VERSION "ev-bms-module-1.0"

NS_ :

BS_:

BU_: BMS VCU

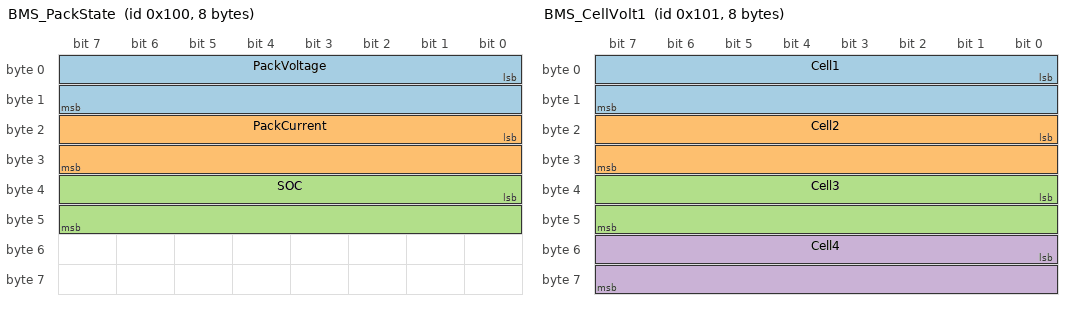
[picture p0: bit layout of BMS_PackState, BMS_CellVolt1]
BO_ 256 BMS_PackState: 8 BMS
 SG_ PackVoltage : 0|16@1+ (0.01,0) [0|655.35] "V" VCU
 SG_ PackCurrent : 16|16@1- (0.1,0) [-3276.8|3276.7] "A" VCU
 SG_ SOC : 32|16@1+ (0.01,0) [0|100] "%" VCU

BO_ 257 BMS_CellVolt1: 8 BMS
 SG_ Cell1 : 0|16@1+ (0.001,0) [0|65.535] "V" VCU
 SG_ Cell2 : 16|16@1+ (0.001,0) [0|65.535] "V" VCU
 SG_ Cell3 : 32|16@1+ (0.001,0) [0|65.535] "V" VCU
 SG_ Cell4 : 48|16@1+ (0.001,0) [0|65.535] "V" VCU

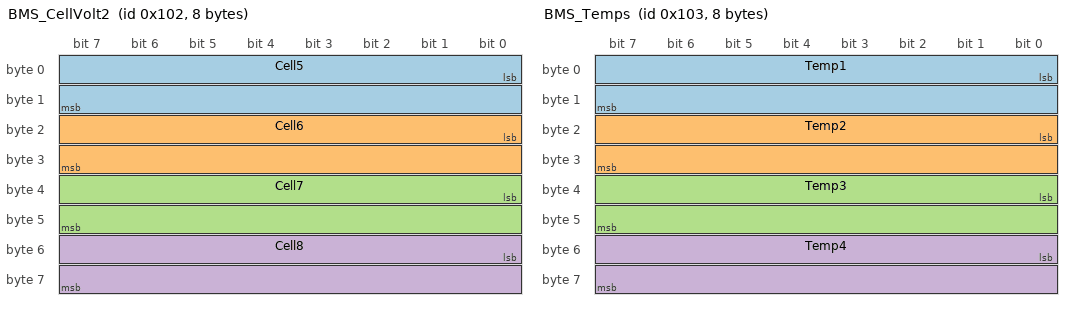
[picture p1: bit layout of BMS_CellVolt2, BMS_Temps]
BO_ 258 BMS_CellVolt2: 8 BMS
 SG_ Cell5 : 0|16@1+ (0.001,0) [0|65.535] "V" VCU
 SG_ Cell6 : 16|16@1+ (0.001,0) [0|65.535] "V" VCU
 SG_ Cell7 : 32|16@1+ (0.001,0) [0|65.535] "V" VCU
 SG_ Cell8 : 48|16@1+ (0.001,0) [0|65.535] "V" VCU

BO_ 259 BMS_Temps: 8 BMS
 SG_ Temp1 : 0|16@1- (0.1,0) [-3276.8|3276.7] "degC" VCU
 SG_ Temp2 : 16|16@1- (0.1,0) [-3276.8|3276.7] "degC" VCU
 SG_ Temp3 : 32|16@1- (0.1,0) [-3276.8|3276.7] "degC" VCU
 SG_ Temp4 : 48|16@1- (0.1,0) [-3276.8|3276.7] "degC" VCU

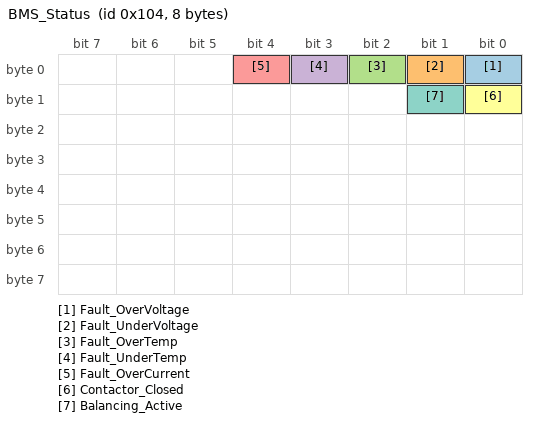
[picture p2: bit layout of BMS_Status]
BO_ 260 BMS_Status: 8 BMS
 SG_ Fault_OverVoltage : 0|1@1+ (1,0) [0|1] "" VCU
 SG_ Fault_UnderVoltage : 1|1@1+ (1,0) [0|1] "" VCU
 SG_ Fault_OverTemp : 2|1@1+ (1,0) [0|1] "" VCU
 SG_ Fault_UnderTemp : 3|1@1+ (1,0) [0|1] "" VCU
 SG_ Fault_OverCurrent : 4|1@1+ (1,0) [0|1] "" VCU
 SG_ Contactor_Closed : 8|1@1+ (1,0) [0|1] "" VCU
 SG_ Balancing_Active : 9|1@1+ (1,0) [0|1] "" VCU

CM_ BO_ 256 "Top-level pack state broadcast at 10 Hz: terminal voltage, current (discharge +), and BMS-reported SOC.";
CM_ BO_ 257 "Cell voltages 1-4, 1 mV resolution, broadcast at 2 Hz.";
CM_ BO_ 258 "Cell voltages 5-8, 1 mV resolution, broadcast at 2 Hz.";
CM_ BO_ 259 "Module temperatures from 4 NTC sensors, 0.1 degC resolution, signed, at 1 Hz.";
CM_ BO_ 260 "Fault flags, contactor and balancing status bitfield at 1 Hz.";
CM_ SG_ 256 PackCurrent "Sign convention: discharge POSITIVE, charge/regen NEGATIVE.";

BA_DEF_ "BusType" STRING ;
BA_DEF_DEF_ "BusType" "CAN";

VAL_ 260 Contactor_Closed 0 "Open" 1 "Closed" ;
VAL_ 260 Balancing_Active 0 "Idle" 1 "Balancing" ;
